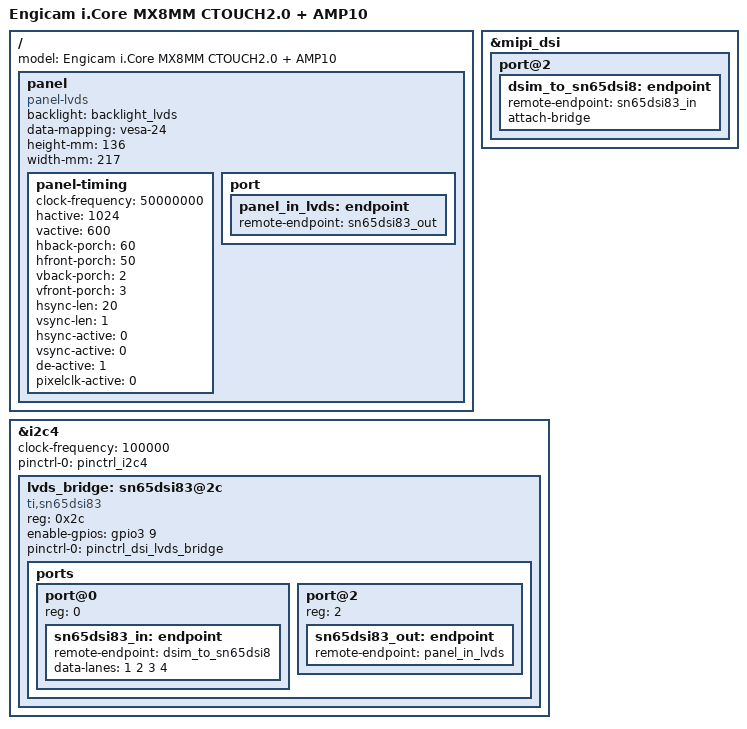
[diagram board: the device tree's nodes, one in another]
// SPDX-License-Identifier: (GPL-2.0+ OR MIT)
/*
 * Copyright 2021 Engicam srl
 * Copyright 2019 NXP
 */

#include "imx8mm-icore-ctouch2-rs232.dts"

/ {
	model = "Engicam i.Core MX8MM CTOUCH2.0 + AMP10";

	panel {
		compatible = "panel-lvds";
		backlight = <&backlight_lvds>;
		data-mapping = "vesa-24";
		height-mm = <136>;
		width-mm = <217>;
		status = "okay";

		panel-timing {
			clock-frequency = <50000000>;
			hactive = <1024>;
			vactive = <600>;
			hback-porch = <60>;
			hfront-porch = <50>;
			vback-porch = <2>;
			vfront-porch = <3>;
			hsync-len = <20>;
			vsync-len = <1>;
			hsync-active = <0>;
			vsync-active = <0>;
			de-active = <1>;
			pixelclk-active = <0>;
		};

		port {
			panel_in_lvds: endpoint {
			remote-endpoint = <&sn65dsi83_out>;
			};
		};
	};
};

&mipi_dsi {
	status = "okay";

	port@2 {
		dsim_to_sn65dsi8: endpoint {
			remote-endpoint = <&sn65dsi83_in>;
			attach-bridge;
		};
	};
};

&i2c4 {
	clock-frequency = <100000>;
	pinctrl-names = "default";
	pinctrl-0 = <&pinctrl_i2c4>;
	status = "okay";

	#address-cells = <1>;
	#size-cells = <0>;

	lvds_bridge: sn65dsi83@2c {
		compatible = "ti,sn65dsi83";
		reg = <0x2c>;

		enable-gpios = <&gpio3 9 GPIO_ACTIVE_HIGH>;
		pinctrl-names = "default";
		pinctrl-0 = <&pinctrl_dsi_lvds_bridge>;
		status = "okay";

		ports {
			#address-cells = <1>;
			#size-cells = <0>;
			port@0 {
				reg = <0>;
				sn65dsi83_in: endpoint {
					remote-endpoint = <&dsim_to_sn65dsi8>;
					data-lanes = <1 2 3 4>;
				};
			};

			port@2 {
				reg = <2>;
				sn65dsi83_out: endpoint {
					remote-endpoint = <&panel_in_lvds>;
				};
			};
		};
	};
};

